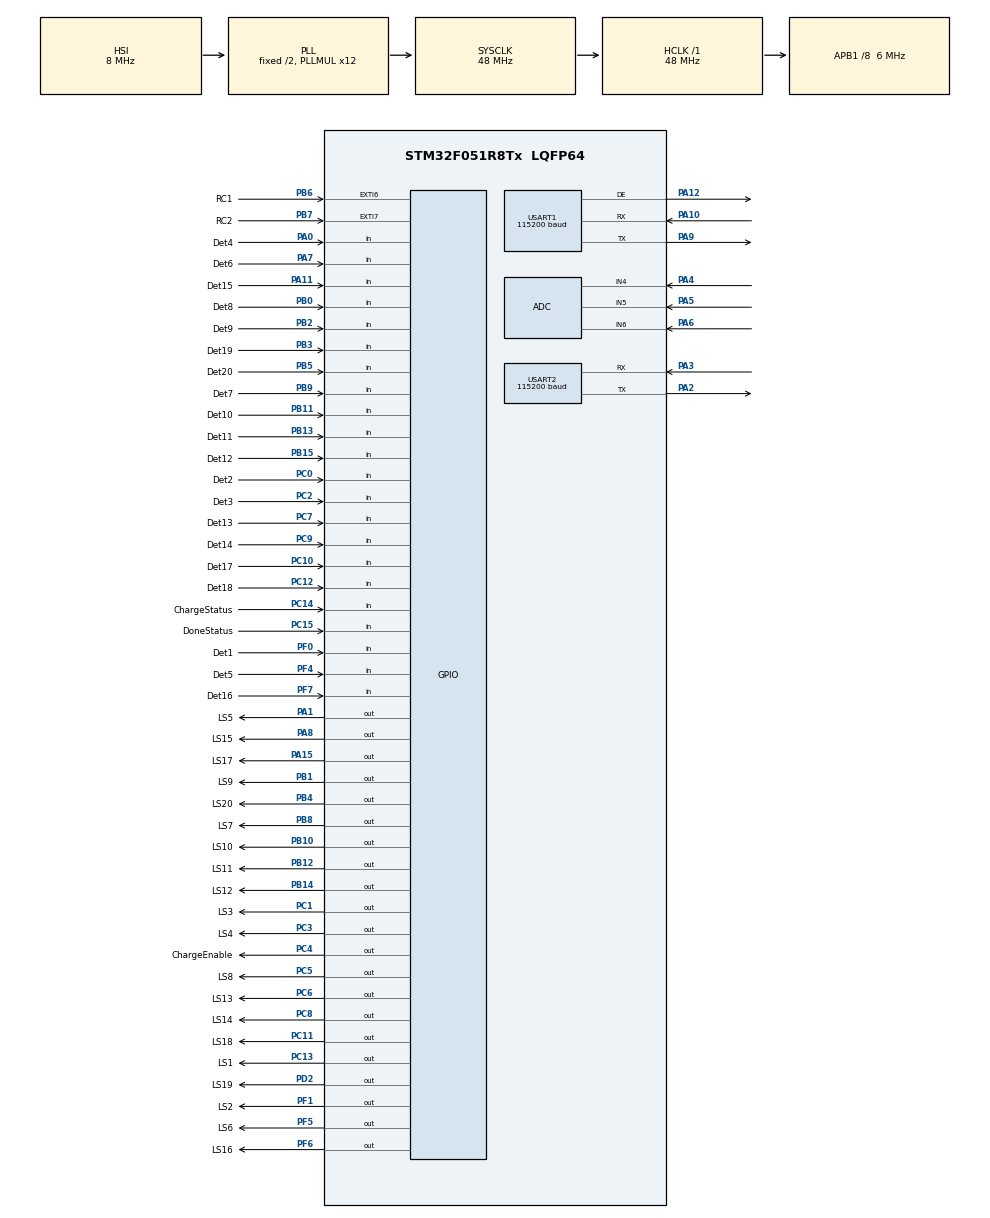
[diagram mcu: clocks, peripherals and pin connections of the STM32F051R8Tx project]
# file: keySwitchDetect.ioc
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ADC.ContinuousConvMode=ENABLE
ADC.DMAContinuousRequests=ENABLE
ADC.EOCSelection=ADC_EOC_SEQ_CONV
ADC.SamplingTime=ADC_SAMPLETIME_41CYCLES_5
Dma.ADC.0.Direction=DMA_PERIPH_TO_MEMORY
Dma.ADC.0.Instance=DMA1_Channel1
Dma.ADC.0.MemDataAlignment=DMA_MDATAALIGN_HALFWORD
Dma.ADC.0.MemInc=DMA_MINC_ENABLE
Dma.ADC.0.Mode=DMA_CIRCULAR
Dma.ADC.0.PeriphDataAlignment=DMA_PDATAALIGN_HALFWORD
Dma.ADC.0.PeriphInc=DMA_PINC_DISABLE
Dma.ADC.0.Priority=DMA_PRIORITY_LOW
Dma.Request0=ADC
IWDG.Prescaler=IWDG_PRESCALER_32
IWDG.Reload=3750
IWDG.Window=3750
Mcu.Family=STM32F0
Mcu.Name=STM32F051R8Tx
Mcu.Package=LQFP64
NVIC.ADC1_COMP_IRQn=true\:2\:0\:true\:false\:true\:true\:true\:true
NVIC.DMA1_Channel1_IRQn=true\:2\:0\:true\:false\:true\:false\:true\:true
NVIC.EXTI4_15_IRQn=true\:3\:0\:true\:false\:true\:true\:true\:true
NVIC.TIM14_IRQn=true\:1\:0\:true\:false\:true\:true\:true\:true
NVIC.USART1_IRQn=true\:0\:0\:false\:false\:true\:true\:true\:true
PA0.GPIO_Label=Det4
PA0.GPIO_PuPd=GPIO_PULLUP
PA0.Signal=GPIO_Input
PA1.GPIO_Label=LS5
PA1.GPIO_Speed=GPIO_SPEED_FREQ_HIGH
PA1.Signal=GPIO_Output
PA10.Mode=Asynchronous
PA10.Signal=USART1_RX
PA11.GPIO_Label=Det15
PA11.GPIO_PuPd=GPIO_PULLUP
PA11.Signal=GPIO_Input
PA12.Mode=Hardware Flow Control (RS485)
PA12.Signal=USART1_DE
PA13.Mode=Serial_Wire
PA13.Signal=SYS_SWDIO
PA14.Mode=Serial_Wire
PA14.Signal=SYS_SWCLK
PA15.GPIO_Label=LS17
PA15.GPIO_Speed=GPIO_SPEED_FREQ_HIGH
PA15.Signal=GPIO_Output
PA2.Mode=Asynchronous
PA2.Signal=USART2_TX
PA3.Mode=Asynchronous
PA3.Signal=USART2_RX
PA4.Mode=IN4
PA4.Signal=ADC_IN4
PA5.Mode=IN5
PA5.Signal=ADC_IN5
PA6.Mode=IN6
PA6.Signal=ADC_IN6
PA7.GPIO_Label=Det6
PA7.GPIO_PuPd=GPIO_PULLUP
PA7.Signal=GPIO_Input
PA8.GPIO_Label=LS15
PA8.Signal=GPIO_Output
PA9.Mode=Asynchronous
PA9.Signal=USART1_TX
PB0.GPIO_Label=Det8
PB0.GPIO_PuPd=GPIO_PULLUP
PB0.Signal=GPIO_Input
PB1.GPIO_Label=LS9
PB1.GPIO_Speed=GPIO_SPEED_FREQ_HIGH
PB1.Signal=GPIO_Output
PB10.GPIO_Label=LS10
PB10.GPIO_Speed=GPIO_SPEED_FREQ_HIGH
PB10.Signal=GPIO_Output
PB11.GPIO_Label=Det10
PB11.GPIO_PuPd=GPIO_PULLUP
PB11.Signal=GPIO_Input
PB12.GPIO_Label=LS11
PB12.GPIO_Speed=GPIO_SPEED_FREQ_HIGH
PB12.Signal=GPIO_Output
PB13.GPIO_Label=Det11
PB13.GPIO_PuPd=GPIO_PULLUP
PB13.Signal=GPIO_Input
PB14.GPIO_Label=LS12
PB14.GPIO_Speed=GPIO_SPEED_FREQ_HIGH
PB14.Signal=GPIO_Output
PB15.GPIO_Label=Det12
PB15.GPIO_PuPd=GPIO_PULLUP
PB15.Signal=GPIO_Input
PB2.GPIO_Label=Det9
PB2.GPIO_PuPd=GPIO_PULLUP
PB2.Signal=GPIO_Input
PB3.GPIO_Label=Det19
PB3.GPIO_PuPd=GPIO_PULLUP
PB3.Signal=GPIO_Input
PB4.GPIO_Label=LS20
PB4.Signal=GPIO_Output
PB5.GPIO_Label=Det20
PB5.GPIO_PuPd=GPIO_PULLUP
PB5.Signal=GPIO_Input
PB6.GPIO_Label=RC1
PB6.Signal=GPXTI6
PB7.GPIO_Label=RC2
PB7.Signal=GPXTI7
PB8.GPIO_FM8=SYSCFG_CFGR1_I2C_FMP_PB8
PB8.GPIO_Label=LS7
PB8.GPIO_Speed=GPIO_SPEED_FREQ_HIGH
PB8.Signal=GPIO_Output
PB9.GPIO_Label=Det7
PB9.GPIO_PuPd=GPIO_PULLUP
PB9.Signal=GPIO_Input
PC0.GPIO_Label=Det2
PC0.GPIO_PuPd=GPIO_PULLUP
PC0.Signal=GPIO_Input
PC1.GPIO_Label=LS3
PC1.GPIO_Speed=GPIO_SPEED_FREQ_HIGH
PC1.Signal=GPIO_Output
PC10.GPIO_Label=Det17
PC10.GPIO_PuPd=GPIO_PULLUP
PC10.Signal=GPIO_Input
PC11.GPIO_Label=LS18
PC11.GPIO_Speed=GPIO_SPEED_FREQ_HIGH
PC11.Signal=GPIO_Output
PC12.GPIO_Label=Det18
PC12.GPIO_PuPd=GPIO_PULLUP
PC12.Signal=GPIO_Input
PC13.GPIO_Label=LS1
PC13.Signal=GPIO_Output
PC14-OSC32_IN.GPIO_Label=ChargeStatus
PC14-OSC32_IN.GPIO_PuPd=GPIO_PULLUP
PC14-OSC32_IN.Signal=GPIO_Input
PC15-OSC32_OUT.GPIO_Label=DoneStatus
PC15-OSC32_OUT.GPIO_PuPd=GPIO_PULLUP
PC15-OSC32_OUT.Signal=GPIO_Input
PC2.GPIO_Label=Det3
PC2.GPIO_PuPd=GPIO_PULLUP
PC2.Signal=GPIO_Input
PC3.GPIO_Label=LS4
PC3.GPIO_Speed=GPIO_SPEED_FREQ_HIGH
PC3.Signal=GPIO_Output
PC4.GPIO_Label=ChargeEnable
PC4.GPIO_Speed=GPIO_SPEED_FREQ_HIGH
PC4.Signal=GPIO_Output
PC5.GPIO_Label=LS8
PC5.GPIO_Speed=GPIO_SPEED_FREQ_HIGH
PC5.Signal=GPIO_Output
PC6.GPIO_Label=LS13
PC6.GPIO_Speed=GPIO_SPEED_FREQ_HIGH
PC6.Signal=GPIO_Output
PC7.GPIO_Label=Det13
PC7.GPIO_PuPd=GPIO_PULLUP
PC7.Signal=GPIO_Input
PC8.GPIO_Label=LS14
PC8.GPIO_Speed=GPIO_SPEED_FREQ_HIGH
PC8.Signal=GPIO_Output
PC9.GPIO_Label=Det14
PC9.GPIO_PuPd=GPIO_PULLUP
PC9.Signal=GPIO_Input
PD2.GPIO_Label=LS19
PD2.GPIO_Speed=GPIO_SPEED_FREQ_HIGH
PD2.Signal=GPIO_Output
PF0-OSC_IN.GPIO_Label=Det1
PF0-OSC_IN.GPIO_PuPd=GPIO_PULLUP
PF0-OSC_IN.Signal=GPIO_Input
PF1-OSC_OUT.GPIO_Label=LS2
PF1-OSC_OUT.GPIO_Speed=GPIO_SPEED_FREQ_HIGH
PF1-OSC_OUT.Signal=GPIO_Output
PF4.GPIO_Label=Det5
PF4.GPIO_PuPd=GPIO_PULLUP
PF4.Signal=GPIO_Input
PF5.GPIO_Label=LS6
PF5.GPIO_Speed=GPIO_SPEED_FREQ_HIGH
PF5.Signal=GPIO_Output
PF6.GPIO_Label=LS16
PF6.GPIO_Speed=GPIO_SPEED_FREQ_HIGH
PF6.Signal=GPIO_Output
PF7.GPIO_Label=Det16
PF7.GPIO_PuPd=GPIO_PULLUP
PF7.Signal=GPIO_Input
ProjectManager.HeapSize=0x200
ProjectManager.StackSize=0x400
ProjectManager.TargetToolchain=MDK-ARM V5.32
RCC.AHBFreq_Value=48000000
RCC.APB1CLKDivider=RCC_HCLK_DIV8
RCC.APB1Freq_Value=6000000
RCC.APB1TimFreq_Value=12000000
RCC.HCLKFreq_Value=48000000
RCC.PLLMUL=RCC_PLL_MUL12
RCC.SYSCLKFreq_VALUE=48000000
RCC.SYSCLKSource=RCC_SYSCLKSOURCE_PLLCLK
TIM14.AutoReloadPreload=TIM_AUTORELOAD_PRELOAD_ENABLE
TIM14.Period=2000
TIM14.Prescaler=0
USART1.BaudRate=115200
USART1.DMADisableonRxErrorParam=ADVFEATURE_DMA_DISABLEONRXERROR
USART1.VirtualMode-Asynchronous=VM_ASYNC
USART1.VirtualMode-Hardware\ Flow\ Control\ (RS485)=VM_ASYNC
USART2.BaudRate=115200
USART2.VirtualMode-Asynchronous=VM_ASYNC
VP_IWDG_VS_IWDG.Mode=IWDG_Activate
VP_TIM14_VS_ClockSourceINT.Mode=Enable_Timer
board=custom

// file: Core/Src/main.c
/* USER CODE BEGIN Header */
/**
  ******************************************************************************
  * @file           : main.c
  * @brief          : Main program body
  ******************************************************************************
  * @attention
  *
  * Copyright (c) 2023 STMicroelectronics.
  * All rights reserved.
  *
  * This software is licensed under terms that can be found in the LICENSE file
  * in the root directory of this software component.
  * If no LICENSE file comes with this software, it is provided AS-IS.
  *
  ******************************************************************************
  */
/* USER CODE END Header */
#include "main.h"
#include "adc.h"
#include "dma.h"
#include "iwdg.h"
#include "tim.h"
#include "usart.h"
#include "gpio.h"

/* USER CODE BEGIN Includes */
#include <stdio.h>
#include "user_protocol.h"
#include "common.h"
#include "user_data.h"
/* USER CODE END Includes */

void SystemClock_Config(void);

int main(void)
{

  /* MCU Configuration--------------------------------------------------------*/

  /* Reset of all peripherals, Initializes the Flash interface and the Systick. */
  HAL_Init();

  /* USER CODE BEGIN Init */
  user_database_init();
  /* USER CODE END Init */

  /* Configure the system clock */
  SystemClock_Config();

  /* Initialize all configured peripherals */
  MX_GPIO_Init();
  MX_DMA_Init();
  MX_ADC_Init();
  MX_IWDG_Init();
  MX_TIM14_Init();
  MX_USART1_UART_Init();
  MX_USART2_UART_Init();
  /* USER CODE BEGIN 2 */
	printSetting();
	user_start_tim();
  /* USER CODE END 2 */

  /* Infinite loop */
  while (1)
  {

    /* USER CODE BEGIN 3 */
		MX_IWDG_Refresh();
		user_protocol_handle();
		user_huart_error_check();
		auto_check_task();
		user_check_device_status();
		user_led_task();
		user_reply_handle();
  }
  /* USER CODE END 3 */
}

void SystemClock_Config(void)
{
  RCC_OscInitTypeDef RCC_OscInitStruct = {0};
  RCC_ClkInitTypeDef RCC_ClkInitStruct = {0};
  RCC_PeriphCLKInitTypeDef PeriphClkInit = {0};

  /** Initializes the RCC Oscillators according to the specified parameters
  * in the RCC_OscInitTypeDef structure.
  */
  RCC_OscInitStruct.OscillatorType = RCC_OSCILLATORTYPE_HSI|RCC_OSCILLATORTYPE_HSI14
                              |RCC_OSCILLATORTYPE_LSI;
  RCC_OscInitStruct.HSIState = RCC_HSI_ON;
  RCC_OscInitStruct.HSI14State = RCC_HSI14_ON;
  RCC_OscInitStruct.HSICalibrationValue = RCC_HSICALIBRATION_DEFAULT;
  RCC_OscInitStruct.HSI14CalibrationValue = 16;
  RCC_OscInitStruct.LSIState = RCC_LSI_ON;
  RCC_OscInitStruct.PLL.PLLState = RCC_PLL_ON;
  RCC_OscInitStruct.PLL.PLLSource = RCC_PLLSOURCE_HSI;
  RCC_OscInitStruct.PLL.PLLMUL = RCC_PLL_MUL12;
  RCC_OscInitStruct.PLL.PREDIV = RCC_PREDIV_DIV1;
  if (HAL_RCC_OscConfig(&RCC_OscInitStruct) != HAL_OK)
  {
    Error_Handler();
  }

  /** Initializes the CPU, AHB and APB buses clocks
  */
  RCC_ClkInitStruct.ClockType = RCC_CLOCKTYPE_HCLK|RCC_CLOCKTYPE_SYSCLK
                              |RCC_CLOCKTYPE_PCLK1;
  RCC_ClkInitStruct.SYSCLKSource = RCC_SYSCLKSOURCE_PLLCLK;
  RCC_ClkInitStruct.AHBCLKDivider = RCC_SYSCLK_DIV1;
  RCC_ClkInitStruct.APB1CLKDivider = RCC_HCLK_DIV8;

  if (HAL_RCC_ClockConfig(&RCC_ClkInitStruct, FLASH_LATENCY_1) != HAL_OK)
  {
    Error_Handler();
  }
  PeriphClkInit.PeriphClockSelection = RCC_PERIPHCLK_USART1;
  PeriphClkInit.Usart1ClockSelection = RCC_USART1CLKSOURCE_PCLK1;
  if (HAL_RCCEx_PeriphCLKConfig(&PeriphClkInit) != HAL_OK)
  {
    Error_Handler();
  }
}

void Error_Handler(void)
{
  __disable_irq();
  while (1)
  {
  }
}
